# STM32MP13xx register map
File version: 1.5
CPU: CA7 r0p0, little endian, MPU, FPU, 4 interrupt priority bits
Registers are 32-bit, read-write, reset 0x0 unless marked. A register's access mark holds for its fields unless they carry their own. Offsets are from the block's base; [hi:lo] are bit positions; {n}, {i} and the like mark numbered series; 'fields as' and 'values as' point back to an identical list.

## RCC (part 3 of 7)
Base 0x50000000
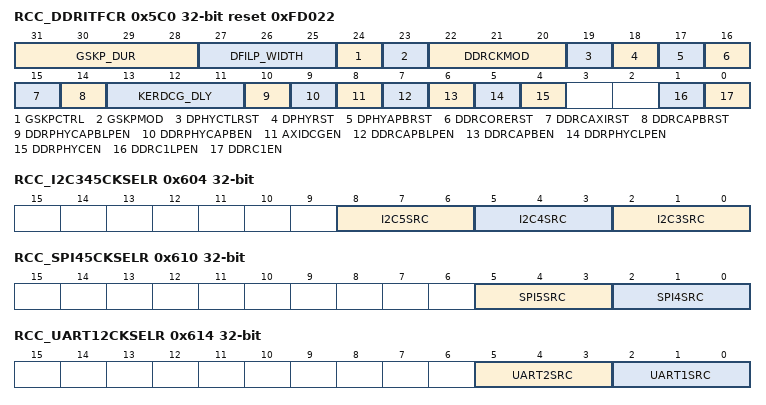
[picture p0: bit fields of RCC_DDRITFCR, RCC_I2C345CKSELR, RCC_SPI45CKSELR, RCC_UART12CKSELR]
0x5C0 RCC_DDRITFCR reset 0xFD022 — RCC DDR interface control register
  [31:28] GSKP_DUR — Glitch skipper duration in automatic mode If DDRC block is configured as secure via the corresponding DECPROT[1] field of the ETZPC register, a write access to this register field must be secure. A read access may be secure or non-secure. Written by software. This field allow the application to define the amount of time where the glitch skipper is providing the clock dphy_ker_ck instead of the clock ddrc_ker_ck to the DDRC block. This feature is only working when the glitch skipper is set in automatic mode (GSKPMOD = '1'). This delay is equal to (GSKP_DUR + 1) x 32 x Tdphy_ker_ck ...
    0=Sets a delay of 32 x Tdphy_ker_ck; 1=Sets a delay of 2 x 32 x Tdphy_ker_ck; 2=Sets a delay of 3 x 32 x Tdphy_ker_ck; 15=Sets a delay of 16 x 32 x Tdphy_ker_ck
  [27:25] DFILP_WIDTH — Minimum duration of low-power request command If DDRC block is configured as secure via the corresponding DECPROT[1] field of the ETZPC register, a write access to this register field must be secure. A read access may be secure or non-secure. Written by software. The low power request duration must always be bigger or equal to 1 microsecond. If this duration is not respected, the DDR interface behavior is not guaranteed. The application has to program properly DFILP_WIDTH in order to ensure a delay bigger or equal to 1 microsecond. Note that the delay is also dependent of the frequency of the dphy_ker_ck clock. Others: Forces a delay of 544 x Tdphy_ker_ck to be used when Fdphy_ker_ck is between 410 and 533MHz
    0=Bypass, delay disabled; 1=Forces a delay of 160 x Tdphy_ker_ck to be used when Fdphy_ker_ck is between 120 and 160 MHz; 2=Forces a delay of 224 x Tdphy_ker_ck to be used when Fdphy_ker_ck is between 160 and 220 MHz; 3=Forces a delay of 320 x Tdphy_ker_ck to be used when Fdphy_ker_ck is between 220 and 320 MHz; 4=Forces a delay of 416 x Tdphy_ker_ck to be used when Fdphy_ker_ck is between 320 and 410 MHz
  [24] GSKPCTRL — Glitch skipper (GSKP) control If DDRC block is configured as secure via the corresponding DECPROT[1] field of the ETZPC register, a write access to this register field must be secure. A read access may be secure or non-secure. Set and clear by software. This has effect only if GSKPMOD = '0'.
    0=The GSKP block is providing the clock phy_out_ck (provided by the DDRPHYC); 1=The GSKP block is providing the clock dphy_ker_ck (provided by the RCC)
  [23] GSKPMOD — Glitch Skipper (GSKP) Mode If DDRC block is configured as secure via the corresponding DECPROT[1] field of the ETZPC register, a write access to this register field must be secure. A read access may be secure or non-secure. Set and clear by software.
    0=The GSKP block is controlled by the GSKPCTRL bit; 1=The GSKP block is controlled automatically by the DFI
  [22:20] DDRCKMOD — RCC mode for DDR clock control If DDRC block is configured as secure via the corresponding DECPROT[1] field of the ETZPC register, a write access to this register field must be secure. A read access may be secure or non-secure. Written by software. This mode can be used when the application wants to maintain a clock to the DLLs in order to avoid the re-lock sequences. In this mode it is recommended to have DDRCxEN = DDRCxLPEN = DDRPHYCEN = DDRPHYCLPEN = '1'. This mode can be used when the DLLs are in bypass. In this mode it is recommended to have DDRCxEN = DDRCxLPEN = DDRPHYCEN = DDRPHYCLPEN = '1'. This mode can be used when the application wants to maintain a clock to the DLLs. In this mode it is recommended to have DDRCxEN = DDRCxLPEN = DDRPHYCEN = DDRPHYCLPEN = '1'. This mode can be used when the DLLs are in bypass. In this mode it is recommended to have DDRCxEN = DDRCxLPEN = DDRPHYCEN = DDRPHYCLPEN = '1'. other: reserved
    0=Normal mode: the gating of the dphy_ker_ck clock depends on the DDRPHYCEN, DDRPHYCLPEN and MPU mode. The gating of the ddrc_ker_ckg clock depends on the DDRCxEN, DDRCxLPEN and MPU mode. This mode must be selected during DDRC and DDRPHYC initialization phase, and if the application is using the software self-refresh (SSR).; 1=Automatic Self-Refresh mode (ASR1): the clock ddrc_ker_ckg is gated automatically according to cactive_ddrc signal. The gating of the dphy_ker_ck clock depends on the DDRPHYCEN, DDRPHYCLPEN and MPU mode.; 5=Full Automatic Self-Refresh mode (ASR2): the clocks ddrc_ker_ckg and dphy_ker_ck are gated automatically according to cactive_ddrc signal; 2=Hardware Self-Refresh mode (HSR1): the gating of the ddrc_ker_ckg clock is controlled by the AXI-Low-Power interface connected to the DDRC. The gating of the dphy_ker_ck clock depends on the DDRPHYCEN, DDRPHYCLPEN and MPU mode.; 6=Full Hardware Self-Refresh mode (HSR2): the gating of ddrc_ker_ckg and dphy_ker_ck clocks are controlled by the AXI-Low-Power interface connected to the DDRC
  [19] DPHYCTLRST — DDRPHYC Control reset If DDRPHYC block is configured as secure via the corresponding DECPROT[1] field of the ETZPC register, a write access to this register field must be secure. A read access may be secure or non-secure. Set and clear by software.
    0=does not reset the DDRPHYC Control; 1=reset the DDRPHYC Control
  [18] DPHYRST — DDRPHYC reset If DDRPHYC block is configured as secure via the corresponding DECPROT[1] field of the ETZPC register, a write access to this register field must be secure. A read access may be secure or non-secure. Set and clear by software.
    0=does not reset the DDRPHYC; 1=reset the DDRPHYC
  [17] DPHYAPBRST — DDRPHYC APB interface reset If DDRPHYC block is configured as secure via the corresponding DECPROT[1] field of the ETZPC register, a write access to this register field must be secure. A read access may be secure or non-secure. Set and clear by software.
    0=does not reset the DDRPHYC APB interface; 1=reset the DDRPHYC APB interface
  [16] DDRCORERST — DDRC core reset If DDRC block is configured as secure via the corresponding DECPROT[1] field of the ETZPC register, a write access to this register field must be secure. A read access may be secure or non-secure. Set and clear by software.
    0=does not reset the DDRC core; 1=reset the DDRC core
  [15] DDRCAXIRST — DDRC AXI interface reset If DDRC block is configured as secure via the corresponding DECPROT[1] field of the ETZPC register, a write access to this register field must be secure. A read access may be secure or non-secure. Set and clear by software.
    0=does not reset the DDRC AXI interface; 1=reset the DDRC AXI interface
  [14] DDRCAPBRST — DDRC APB interface reset If DDRC block is configured as secure via the corresponding DECPROT[1] field of the ETZPC register, a write access to this register field must be secure. A read access may be secure or non-secure. Set and clear by software.
    0=does not reset the DDRC APB interface; 1=reset the DDRC APB interface
  [13:11] KERDCG_DLY — AXIDCG delay If DDRC block is configured as secure via the corresponding DECPROT[1] field of the ETZPC register, a write access to this register field must be secure. A read access may be secure or non-secure. Set and clear by software. It represents the delay between the falling edge of the cactive_ddrc signal and the moment where the KERDCG will gate the ddrc_ker_ckg. ...
    0=1 period of ddrc_ker_ck between cactive_ddrc falling edge and the gating of ddrc_ker_ckg; 1=3 periods of ddrc_ker_ck between cactive_ddrc falling edge and the gating of ddrc_ker_ckg; 7=15 periods of ddrc_ker_ck between cactive_ddrc falling edge and the gating of ddrc_ker_ckg
  [10] DDRPHYCAPBLPEN — DDRPHYC APB clock enable during CSleep mode If DDRC block is configured as secure via the corresponding DECPROT[1] field of the ETZPC register, a write access to this register field must be secure. A read access may be secure or non-secure. Set and clear by software. This bit is controlling the gating of pclk4_dphy clock during CSleep mode.
    0=means that the APB clock is disabled in CSleep; 1=means that the APB clock is enabled in CSleep
  [9] DDRPHYCAPBEN — DDRPHYC APB clock enable If DDRC block is configured as secure via the corresponding DECPROT[1] field of the ETZPC register, a write access to this register field must be secure. A read access may be secure or non-secure. Set and clear by software. This bit is controlling the gating of pclk4_dphy clock.
    0=means that the APB clock is disabled; 1=means that the APB clock is enabled
  [8] AXIDCGEN — AXIDCG enable during MPU CRun mode If DDRC block is configured as secure via the corresponding DECPROT[1] field of the ETZPC register, a write access to this register field must be secure. A read access may be secure or non-secure. Set and clear by software. When the dynamic clock gating is disabled, the clock is always provided to the DDRC if provided by the RCC.
    0=means that the dynamic clock gating of AXIDCG[2:1] is disabled during MPU CRun,; 1=means that the dynamic clock gating of AXIDCG[2:1] is enabled during MPU CRun
  [7] DDRCAPBLPEN — DDRC APB clock enable during CSleep mode If DDRC block is configured as secure via the corresponding DECPROT[1] field of the ETZPC register, a write access to this register field must be secure. A read access may be secure or non-secure. Set and clear by software. This bit is controlling the gating of pclk4_ddrc clock during CSleep mode.
    values as DDRPHYCAPBLPEN
  [6] DDRCAPBEN — DDRC APB clock enable If DDRC block is configured as secure via the corresponding DECPROT[1] field of the ETZPC register, a write access to this register field must be secure. A read access may be secure or non-secure. Set and clear by software. This bit is controlling the gating of pclk4_ddrc clock.
    values as DDRPHYCAPBEN
  [5] DDRPHYCLPEN — DDRPHYC peripheral clocks enable during CSleep mode If DDRPHYC block is configured as secure via the corresponding DECPROT[1] field of the ETZPC register, a write access to this register field must be secure. A read access may be secure or non-secure. Set and clear by software. This bit is controlling the gating of dphy_ker_ck and pclk4_dphy in CSleep
    0=means that the peripheral clocks are disabled in CSleep; 1=means that the peripheral clocks are enabled in CSleep
  [4] DDRPHYCEN — DDRPHYC peripheral clocks enable If DDRPHYC block is configured as secure via the corresponding DECPROT[1] field of the ETZPC register, a write access to this register field must be secure. A read access may be secure or non-secure. Set and clear by software. This bit is controlling the gating of dphy_ker_ck and pclk4_dphy
    0=means that the peripheral clocks are disabled; 1=means that the peripheral clocks are enabled
  [1] DDRC1LPEN — DDRC port 1 peripheral clocks enable during CSleep mode If DDRC block is configured as secure via the corresponding DECPROT[1] field of the ETZPC register, a write access to this register field must be secure. A read access may be secure or non-secure. Set and clear by software. This bit is controlling the gating of ddrc_ker_ckg, aclk1_ddrc and pclk4_ddrc in CSleep.
    values as DDRPHYCLPEN
  [0] DDRC1EN — DDRC port 1 peripheral clocks enable If DDRC block is configured as secure via the corresponding DECPROT[1] field of the ETZPC register, a write access to this register field must be secure. A read access may be secure or non-secure. Set and clear by software. This bit is controlling the gating of ddrc_ker_ckg, aclk1_ddrc and pclk4_ddrc clocks.
    0=Means that the DDRC peripheral clocks are disabled; 1=Means that the DDRC peripheral clocks are enabled
0x600 RCC_I2C12CKSELR — RCC I2C1 and I2C2 kernel clock selection register
  [2:0] I2C12SRC — I2C1 and I2C2 kernel clock source selection Written by software. others: reserved, the kernel clock is disabled
    0=pclk1 clock selected as kernel peripheral clock (default after reset); 1=pll4_r_ck clock selected as kernel peripheral clock; 2=hsi_ker_ck clock selected as kernel peripheral clock; 3=csi_ker_ck clock selected as kernel peripheral clock
0x604 RCC_I2C345CKSELR — RCC I2C3, I2C4 and I2C5 kernel clock selection register.
  [all] fields
    0=pclk6 clock selected as kernel peripheral clock (default after reset); 1=pll4_r_ck clock selected as kernel peripheral clock; 2=hsi_ker_ck clock selected as kernel peripheral clock; 3=csi_ker_ck clock selected as kernel peripheral clock
  [8:6] I2C5SRC — I2C5 kernel clock source selection If I2C5 block is configured as secure via the corresponding DECPROT[1] field of the ETZPC register, a write access to this register field must be secure. A read access may be secure or non-secure. Written by software. others: reserved, the kernel clock is disabled
  [5:3] I2C4SRC — I2C4 kernel clock source selection If I2C4 block is configured as secure via the corresponding DECPROT[1] field of the ETZPC register, a write access to this register field must be secure. A read access may be secure or non-secure. Written by software. others: reserved, the kernel clock is disabled
  [2:0] I2C3SRC — I2C3 kernel clock source selection If I2C3 block is configured as secure via the corresponding DECPROT[1] field of the ETZPC register, a write access to this register field must be secure. A read access may be secure or non-secure. Written by software. others: reserved, the kernel clock is disabled
0x608 RCC_SPI2S1CKSELR — RCC SPI/I2S1 kernel clock selection register
  [2:0] SPI1SRC — SPI/I2S1 kernel clock source selection Written by software. others: reserved, the kernel clock is disabled
    0=pll4_p_ck clock selected as kernel peripheral clock (default after reset); 1=pll3_q_ck clock selected as kernel peripheral clock; 2=I2S_CKIN clock selected as kernel peripheral clock; 3=per_ck clock selected as kernel peripheral clock; 4=pll3_r_ck clock selected as kernel peripheral clock
0x60C RCC_SPI2S23CKSELR — RCC SPI/I2S2 and SPI/I2S3 kernel clock selection register
  [2:0] SPI23SRC — SPI/I2S2 and SPI/I2S3 kernel clock source selection Written by software. others: reserved, the kernel clock is disabled
    values as RCC_SPI2S1CKSELR.SPI1SRC
0x610 RCC_SPI45CKSELR — RCC SPI/I2S4 and SPI5 kernel clock selection register
  [5:3] SPI5SRC — SPI5 kernel clock source selection If SPI5 block is configured as secure via the corresponding DECPROT[1] field of the ETZPC register, a write access to this register field must be secure. A read access may be secure or non-secure. Written by software. others: reserved, the kernel clock is disabled
    0=pclk6 clock selected as kernel peripheral clock (default after reset); 1=pll4_q_ck clock selected as kernel peripheral clock; 2=hsi_ker_ck clock selected as kernel peripheral clock; 3=csi_ker_ck clock selected as kernel peripheral clock; 4=hse_ker_ck clock selected as kernel peripheral clock
  [2:0] SPI4SRC — SPI/I2S4 kernel clock source selection If SPI/I2S4 block is configured as secure via the corresponding DECPROT[1] field of the ETZPC register, a write access to this register field must be secure. A read access may be secure or non-secure. Written by software. others: reserved, the kernel clock is disabled
    0=pclk6 clock selected as kernel peripheral clock (default after reset); 1=pll4_q_ck clock selected as kernel peripheral clock; 2=hsi_ker_ck clock selected as kernel peripheral clock; 3=csi_ker_ck clock selected as kernel peripheral clock; 4=hse_ker_ck clock selected as kernel peripheral clock; 5=I2S_CKIN clock selected as kernel peripheral clock
0x614 RCC_UART12CKSELR — RCC USART1 and USART2 kernel clock selection register
  [5:3] UART2SRC — USART2 kernel clock source selection If USART2 block is configured as secure via the corresponding DECPROT[1] field of the ETZPC register, a write access to this register field must be secure. A read access may be secure or non-secure. Written by software. others: reserved, the kernel clock is disabled
    0=pclk6 clock selected as kernel peripheral clock (default after reset); 1=pll3_q_ck clock selected as kernel peripheral clock; 2=hsi_ker_ck clock selected as kernel peripheral clock; 3=csi_ker_ck clock selected as kernel peripheral clock; 4=pll4_q_ck clock selected as kernel peripheral clock; 5=hse_ker_ck clock selected as kernel peripheral clock
  [2:0] UART1SRC — USART1 kernel clock source selection If USART1 block is configured as secure via the corresponding DECPROT[1] field of the ETZPC register, a write access to this register field must be secure. A read access may be secure or non-secure. Written by software. others: reserved, the kernel clock is disabled
    values as UART2SRC
0x618 RCC_UART35CKSELR — RCC USART3 and UART5 kernel clock selection register
  [2:0] UART35SRC — USART3 and UART5 kernel clock source selection Written by software. others: reserved, the kernel clock is disabled
    0=pclk1 clock selected as kernel peripheral clock (default after reset); 1=pll4_q_ck clock selected as kernel peripheral clock; 2=hsi_ker_ck clock selected as kernel peripheral clock; 3=csi_ker_ck clock selected as kernel peripheral clock; 4=hse_ker_ck clock selected as kernel peripheral clock
0x61C RCC_UART4CKSELR — RCC UART4 kernel clock selection register
  [2:0] UART4SRC — UART4 kernel clock source selection Written by software. others: reserved, the kernel clock is disabled
    values as RCC_UART35CKSELR.UART35SRC
0x620 RCC_UART6CKSELR — RCC USART6 kernel clock selection register
  [2:0] UART6SRC — USART6 kernel clock source selection Written by software. others: reserved, the kernel clock is disabled
    0=pclk2 clock selected as kernel peripheral clock (default after reset); 1=pll4_q_ck clock selected as kernel peripheral clock; 2=hsi_ker_ck clock selected as kernel peripheral clock; 3=csi_ker_ck clock selected as kernel peripheral clock; 4=hse_ker_ck clock selected as kernel peripheral clock
0x624 RCC_UART78CKSELR — RCC UART7 and UART8 kernel clock selection register
  [2:0] UART78SRC — UART7 and UART8 kernel clock source selection Written by software. others: reserved, the kernel clock is disabled
    values as RCC_UART35CKSELR.UART35SRC
0x628 RCC_LPTIM1CKSELR — RCC LPTIM1 kernel clock selection register
  [2:0] LPTIM1SRC — LPTIM1 kernel clock source selection Written by software. others: the kernel clock is disabled
    0=pclk1 clock selected as kernel peripheral clock (default after reset); 1=pll4_p_ck clock selected as kernel peripheral clock; 2=pll3_q_ck clock selected as kernel peripheral clock; 3=lse_ck clock selected as kernel peripheral clock; 4=lsi_ck clock selected as kernel peripheral clock; 5=per_ck clock selected as kernel peripheral clock
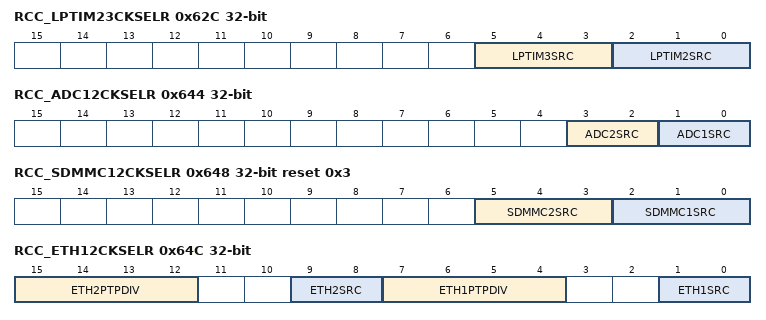
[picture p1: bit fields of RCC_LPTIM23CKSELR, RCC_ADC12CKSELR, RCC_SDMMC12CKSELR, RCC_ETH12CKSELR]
0x62C RCC_LPTIM23CKSELR — RCC LPTIM2 and LPTIM3 kernel clock selection register
  [5:3] LPTIM3SRC — LPTIM3 kernel clock source selection If LPTIM3 block is configured as secure via the corresponding DECPROT[1] field of the ETZPC register, a write access to this register field must be secure. A read access may be secure or non-secure. Written by software. others: the kernel clock is disabled
    0=pclk3 clock selected as kernel peripheral clock (default after reset); 1=pll4_q_ck clock selected as kernel peripheral clock; 2=per_ck clock selected as kernel peripheral clock; 3=lse_ck clock selected as kernel peripheral clock; 4=lsi_ck clock selected as kernel peripheral clock
  [2:0] LPTIM2SRC — LPTIM2 kernel clock source selection If LPTIM2 block is configured as secure via the corresponding DECPROT[1] field of the ETZPC register, a write access to this register field must be secure. A read access may be secure or non-secure. Written by software. others: the kernel clock is disabled
    values as LPTIM3SRC
0x630 RCC_LPTIM45CKSELR — RCC LPTIM4 and LPTIM5 kernel clock selection register
  [2:0] LPTIM45SRC — LPTIM4 and LPTIM5 kernel clock source selection Written by software. others: the kernel clock is disabled
    0=pclk3 clock selected as kernel peripheral clock (default after reset); 1=pll4_p_ck clock selected as kernel peripheral clock; 2=pll3_q_ck clock selected as kernel peripheral clock; 3=lse_ck clock selected as kernel peripheral clock; 4=lsi_ck clock selected as kernel peripheral clock; 5=per_ck clock selected as kernel peripheral clock
0x634 RCC_SAI1CKSELR — RCC SAI1 kernel clock selection register
  [2:0] SAI1SRC — SAI1 and DFSDM kernel clock source selection Written by software. others: reserved, the kernel clock is disabled
    0=pll4_q_ck clock selected as kernel peripheral clock (default after reset); 1=pll3_q_ck clock selected as kernel peripheral clock; 2=I2S_CKIN clock selected as kernel peripheral clock; 3=per_ck clock selected as kernel peripheral clock; 4=pll3_r_ck clock selected as kernel peripheral clock
0x638 RCC_SAI2CKSELR — RCC SAI2 kernel clock selection register
  [2:0] SAI2SRC — SAI2 kernel clock source selection Written by software. others: reserved, the kernel clock is disabled
    0=pll4_q_ck clock selected as kernel peripheral clock (default after reset); 1=pll3_q_ck clock selected as kernel peripheral clock; 2=I2S_CKIN clock selected as kernel peripheral clock; 3=per_ck clock selected as kernel peripheral clock; 4=spdif_ck_symb clock from SPDIFRX selected as kernel peripheral clock; 5=pll3_r_ck clock selected as kernel peripheral clock
0x63C RCC_FDCANCKSELR — RCC FDCAN kernel clock selection register
  [1:0] FDCANSRC — FDCAN kernel clock source selection Written by software.
    0=hse_ker_ck clock selected as kernel peripheral clock (default after reset); 1=pll3_q_ck clock selected as kernel peripheral clock; 2=pll4_q_ck clock selected as kernel peripheral clock; 3=pll4_r_ck clock selected as kernel peripheral clock
0x640 RCC_SPDIFCKSELR — RCC SPDIFRX kernel clock selection register
  [1:0] SPDIFSRC — SPDIFRX kernel clock source selection Written by software. others: reserved, the kernel clock is disabled
    0=pll4_p_ck clock selected as kernel peripheral clock (default after reset); 1=pll3_q_ck clock selected as kernel peripheral clock; 2=hsi_ker_ck clock selected as kernel peripheral clock
0x644 RCC_ADC12CKSELR — This register may be separately and securely write-protected at a field level depending on the secure state of the corresponding peripheral, i.e. depending on the corresponding DECPROT[1] field of the ETZPC register. This register is used to control the selection of the kernel clock for the (AHB2) ADC1 and ADC2 blocks. Note that changing the clock source on-the-fly is allowed, and will not generate any timing violation, however the user has to ensure that both the previous and the new clock sources are present during the switching, and for the whole transition time. Refer to SectionÂ : Clock enabling delays.
  [3:2] ADC2SRC — ADC2 kernel clock source selection If ADC2 block is configured as secure via the corresponding DECPROT[1] field of the ETZPC register, a write access to this register field must be secure. A read access may be secure or non-secure. Written by software. others: the kernel clock is disabled
    0=pll4_r_ck clock selected as kernel peripheral clock (default after reset); 1=per_ck clock selected as kernel peripheral clock; 2=pll3_q_ck clock selected as kernel peripheral clock
  [1:0] ADC1SRC — ADC1 kernel clock source selection If ADC1 block is configured as secure via the corresponding DECPROT[1] field of the ETZPC register, a write access to this register field must be secure. A read access may be secure or non-secure. Written by software. others: the kernel clock is disabled
    values as ADC2SRC
0x648 RCC_SDMMC12CKSELR reset 0x3 — This register may be separately and securely write-protected at a field level depending on the secure state of the corresponding peripheral, i.e. depending on the corresponding DECPROT[1] field of the ETZPC register. This register is used to control the selection of the kernel clock for the (AHB6) SDMMC1 and SDMMC2. Note that changing the clock source on-the-fly is allowed, and will not generate any timing violation, however the user has to ensure that both the previous and the new clock sources are present during the switching, and for the whole transition time. Refer to SectionÂ : Clock enabling delays.
  [5:3] SDMMC2SRC — SDMMC2 kernel clock source selection If SDMMC2 block is configured as secure via the corresponding DECPROT[1] field of the ETZPC register, a write access to this register field must be secure. A read access may be secure or non-secure. Written by software. others: reserved, the kernel clock is disabled
    0=hclk6 clock selected as kernel peripheral clock; 1=pll3_r_ck clock selected as kernel peripheral clock; 2=pll4_p_ck clock selected as kernel peripheral clock; 3=hsi_ker_ck clock selected as kernel peripheral clock (default after reset)
  [2:0] SDMMC1SRC — SDMMC1 kernel clock source selection If SDMMC1 block is configured as secure via the corresponding DECPROT[1] field of the ETZPC register, a write access to this register field must be secure. A read access may be secure or non-secure. Written by software. others: reserved, the kernel clock is disabled
    values as SDMMC2SRC
0x64C RCC_ETH12CKSELR — This register may be separately and securely write-protected at a field level depending on the secure state of the corresponding peripheral, i.e. depending on the corresponding DECPROT[1] field of the ETZPC register. This register is used to control the selection of the kernel clock for the ETH1 and ETH2 blocks. Note that changing the clock source on-the-fly is allowed, and will not generate any timing violation, however the user has to ensure that both the previous and the new clock sources are present during the switching, and for the whole transition time. Refer to SectionÂ : Clock enabling delays.
  [15:12] ETH2PTPDIV — ETH2 clock divider for Precision Time Protocol (PTP) If ETH2 block is configured as secure via the corresponding DECPROT[1] field of the ETZPC register, a write access to this register field must be secure. A read access may be secure or non-secure. Written by software to configure the divider value. ...
    0=bypass (default after reset); 1=division by 2; 2=division by 3; 15=division by 16
  [9:8] ETH2SRC — ETH2 kernel clock source selection If ETH2 block is configured as secure via the corresponding DECPROT[1] field of the ETZPC register, a write access to this register field must be secure. A read access may be secure or non-secure. Written by software. others: the kernel clock is disabled
    0=pll4_p_ck clock selected as kernel peripheral clock (default after reset); 1=pll3_q_ck clock selected as kernel peripheral clock
  [7:4] ETH1PTPDIV — ETH1 clock divider for Precision Time Protocol (PTP) If ETH1 block is configured as secure via the corresponding DECPROT[1] field of the ETZPC register, a write access to this register field must be secure. A read access may be secure or non-secure. Written by software to configure the divider value. ...
    values as ETH2PTPDIV
  [1:0] ETH1SRC — ETH1 kernel clock source selection If ETH1 block is configured as secure via the corresponding DECPROT[1] field of the ETZPC register, a write access to this register field must be secure. A read access may be secure or non-secure. Written by software. others: the kernel clock is disabled
    values as ETH2SRC
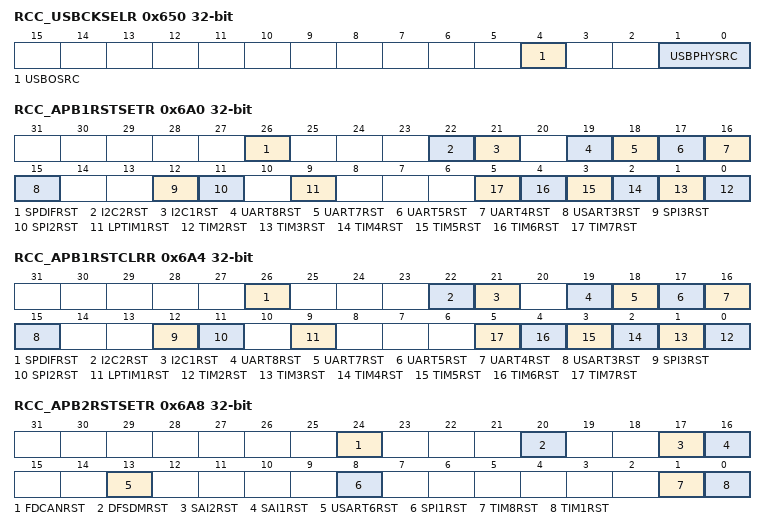
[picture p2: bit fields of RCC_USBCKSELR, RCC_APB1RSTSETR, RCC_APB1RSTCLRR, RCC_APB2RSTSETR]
0x650 RCC_USBCKSELR — This register may be separately and securely write-protected at a field level depending on the secure state of the corresponding peripheral, i.e. depending on the corresponding DECPROT[1] field of the ETZPC register. This register is used to control the selection of the kernel clock for the USBPHY PLL of the USB Host (USBH) and the USB On-The-Go (USBO). It also controls the pre-divider for the reference clock for the USBPHY. Note that changing the clock source on-the-fly is allowed, and will not generate any timing violation, however the user has to ensure that both the previous and the new clock sources are present during the switching, and for the whole transition time. Refer to SectionÂ : Clock enabling delays.
  [4] USBOSRC — USB OTG kernel clock source selection If USBO block is configured as secure via the corresponding DECPROT[1] field of the ETZPC register, a write access to this register field must be secure. A read access may be secure or non-secure. Written by software.
    0=pll4_r_ck clock selected as kernel peripheral clock (default after reset); 1=clock provided by the USB PHY (rcc_ck_usbo_48m) selected as kernel peripheral clock
  [1:0] USBPHYSRC — USB PHY kernel clock source selection If USBPHY block is configured as secure via the corresponding DECPROT[1] field of the ETZPC register, a write access to this register field must be secure. A read access may be secure or non-secure. Written by software. other: clock disabled
    0=hse_ker_ck clock selected as kernel peripheral clock (default after reset); 1=pll4_r_ck clock selected as kernel peripheral clock; 2=hse_ker_ck/2 clock selected as kernel peripheral clock
0x654 RCC_QSPICKSELR — If (AHB6) QUADSPI is configured as secure via the corresponding DECPROT[1] field of the ETZPC register, a write access to this register must be secure. A read access may be secure or non-secure. This register is used to control the selection of the kernel clock for the QUADSPI. Note that changing the clock source on-the-fly is allowed, and will not generate any timing violation, however the user has to ensure that both the previous and the new clock sources are present during the switching, and for the whole transition time. Refer to SectionÂ : Clock enabling delays.
  [1:0] QSPISRC — QUADSPI kernel clock source selection Written by software.
    0=aclk clock selected as kernel peripheral clock (default after reset); 1=pll3_r_ck clock selected as kernel peripheral clock; 2=pll4_p_ck clock selected as kernel peripheral clock; 3=per_ck clock selected as kernel peripheral clock
0x658 RCC_FMCCKSELR — If (AHB6) FMC is configured as secure via the corresponding DECPROT[1] field of the ETZPC register, a write access to this register must be secure. A read access may be secure or non-secure. This register is used to control the selection of the kernel clock for the FMC block. Note that changing the clock source on-the-fly is allowed, and will not generate any timing violation, however the user has to ensure that both the previous and the new clock sources are present during the switching, and for the whole transition time. Refer to SectionÂ : Clock enabling delays.
  [1:0] FMCSRC — FMC kernel clock source selection Written by software.
    values as RCC_QSPICKSELR.QSPISRC
0x65C RCC_RNG1CKSELR — If (AHB5) RNG1 is configured as secure via the corresponding DECPROT[1] field of the ETZPC register, a write access to this register must be secure. A read access may be secure or non-secure. This register is used to control the selection of the kernel clock for the RNG1. Note that changing the clock source on-the-fly is allowed, and will not generate any timing violation, however the user has to ensure that both the previous and the new clock sources are present during the switching, and for the whole transition time. Refer to SectionÂ : Clock enabling delays.
  [1:0] RNG1SRC — RNG1 kernel clock source selection Written by software.
    0=csi_ker_ck clock selected as kernel peripheral clock (default after reset); 1=pll4_r_ck clock selected as kernel peripheral clock; 2=lse_ck clock selected as kernel peripheral clock; 3=lsi_ck clock selected as kernel peripheral clock
0x660 RCC_STGENCKSELR — If (APB5) STGENC is configured as secure via the corresponding DECPROT[1] field of the ETZPC register, a write access to this register must be secure. A read access may be secure or non-secure. STGEN is a dual APB interface IP, with STGENC APB5 controller part which may be secure or non-secure depending on the corresponding DECPROT[1]. Its other STGENRO APB4 read-only interface is non-secure. This register is used to select the peripheral clock for the STGEN block. Note that this clock is used to provide a time reference for the application. Refer to SectionÂ : Clock enabling delays.
  [1:0] STGENSRC — Oscillator selection for kernel clock Set and cleared by software. others: Clock disabled
    0=hsi_ker_ck clock selected (default after reset); 1=hse_ker_ck clock selected
0x664 RCC_DCMIPPCKSELR — If (APB4) DCMIPP is configured as secure via the corresponding DECPROT[1] field of the ETZPC register, a write access to this register must be secure. A read access may be secure or non-secure. This register is used to control the selection of the kernel clock for the DCMIPP block. Note that changing the clock source on-the-fly is allowed, and will not generate any timing violation, however the user has to ensure that both the previous and the new clock sources are present during the switching, and for the whole transition time. Refer to SectionÂ : Clock enabling delays.
  [1:0] DCMIPPSRC — DCMIPP kernel clock source selection Written by software.
    0=aclk clock selected as kernel peripheral clock (default after reset); 1=pll2_q_ck clock selected as kernel peripheral clock; 2=pll4_p_ck clock selected as kernel peripheral clock; 3=per_ck clock selected as kernel peripheral clock
0x668 RCC_SAESCKSELR — If (AHB5) SAES is configured as secure via the corresponding DECPROT[1] field of the ETZPC register, a write access to this register must be secure. A read access may be secure or non-secure. This register is used to control the selection of the kernel clock for the SAES block. Note that changing the clock source on-the-fly is allowed, and will not generate any timing violation, however the user has to ensure that both the previous and the new clock sources are present during the switching, and for the whole transition time. Refer to SectionÂ : Clock enabling delays.
  [1:0] SAESSRC — SAES kernel clock source selection Written by software.
    0=axiss_ck clock selected as kernel peripheral clock (default after reset); 1=per_ck clock selected as kernel peripheral clock; 2=pll_4_r_ck clock selected as kernel peripheral clock; 3=lsi_ck clock selected as kernel peripheral clock
0x6A0 RCC_APB1RSTSETR — This register is used to activate the reset of the corresponding peripheral. Writing '0' has no effect, reading will return the effective values of the corresponding bits. Writing a '1' activates the reset of the corresponding peripheral.
  [all] fields
    0=Writing '0' has no effect, reading '0' means that the block reset is released; 1=Writing '1' asserts the block reset, reading '1' means that the block reset is asserted
  [26] SPDIFRST — SPDIFRX block reset Set by software.
  [22] I2C2RST — I2C2 block reset Set by software.
  [21] I2C1RST — I2C1 block reset Set by software.
  [19] UART8RST — UART8 block reset Set by software.
  [18] UART7RST — UART7 block reset Set by software.
  [17] UART5RST — UART5 block reset Set by software.
  [16] UART4RST — UART4 block reset Set by software.
  [15] USART3RST — USART3 block reset Set by software.
  [12] SPI3RST — SPI3 block reset Set by software.
  [11] SPI2RST — SPI/I2S2 block reset Set by software.
  [9] LPTIM1RST — LPTIM1 block reset Set by software.
  [n-2] TIM{n}RST (n=2..7) — TIM{n} block reset Set by software.
0x6A4 RCC_APB1RSTCLRR — This register is used to release the reset of the corresponding peripheral. Writing '0' has no effect, reading will return the effective values of the corresponding bits. Writing a '1' releases the reset of the corresponding peripheral.
  [all] fields
    0=Writing '0' has no effect, reading '0' means that the block reset is released; 1=Writing '1' release the block reset, reading '1' means that the block reset is asserted
  [26] SPDIFRST — SPDIFRX block reset Cleared by software.
  [22] I2C2RST — I2C2 block reset Cleared by software.
  [21] I2C1RST — I2C1 block reset Cleared by software.
  [19] UART8RST — UART8 block reset Cleared by software.
  [18] UART7RST — UART7 block reset Cleared by software.
  [17] UART5RST — UART5 block reset Cleared by software.
  [16] UART4RST — UART4 block reset Cleared by software.
  [15] USART3RST — USART3 block reset Cleared by software.
  [12] SPI3RST — SPI3 block reset Cleared by software.
  [11] SPI2RST — SPI2 block reset Cleared by software.
  [9] LPTIM1RST — LPTIM1 block reset Cleared by software.
  [n-2] TIM{n}RST (n=2..7) — TIM{n} block reset Cleared by software.
0x6A8 RCC_APB2RSTSETR — This register is used to activate the reset of the corresponding peripheral. Writing '0' has no effect, reading will return the effective values of the corresponding bits. Writing a '1' activates the reset of the corresponding peripheral.
  [all] fields
    values as the fields of RCC_APB1RSTSETR
  [24] FDCANRST — FDCAN block reset Set by software.
  [20] DFSDMRST — DFSDM block reset Set by software.
  [17] SAI2RST — SAI2 block reset Set by software.
  [16] SAI1RST — SAI1 block reset Set by software.
  [13] USART6RST — USART6 block reset Set by software.
  [8] SPI1RST — SPI/I2S1 block reset Set by software.
  [1] TIM8RST — TIM8 block reset Set by software.
  [0] TIM1RST — TIM1 block reset Set by software.
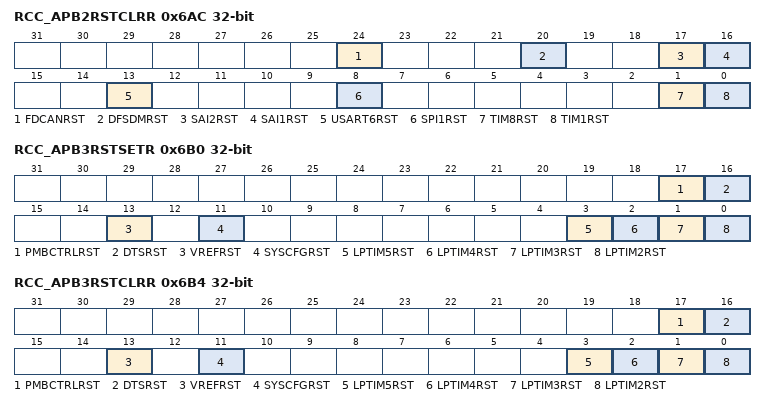
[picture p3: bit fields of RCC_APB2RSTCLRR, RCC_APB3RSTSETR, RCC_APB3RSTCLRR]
0x6AC RCC_APB2RSTCLRR — This register is used to release the reset of the corresponding peripheral. Writing '0' has no effect, reading will return the effective values of the corresponding bits. Writing a '1' releases the reset of the corresponding peripheral.
  [all] fields
    0=Writing '0' has no effect, reading '0' means that the block reset is released; 1=Writing '1' releases the block reset, reading '1' means that the block reset is asserted
  [24] FDCANRST — FDCAN block reset Cleared by software.
  [20] DFSDMRST — DFSDM block reset Cleared by software.
  [17] SAI2RST — SAI2 block reset Cleared by software.
  [16] SAI1RST — SAI1 block reset Cleared by software.
  [13] USART6RST — USART6 block reset Cleared by software.
  [8] SPI1RST — SPI/I2S1 block reset Cleared by software.
  [1] TIM8RST — TIM8 block reset Cleared by software.
  [0] TIM1RST — TIM1 block reset Cleared by software.
0x6B0 RCC_APB3RSTSETR — This register may be separately and securely write-protected at a field level, as detailed in the following register fields description. This register is used to activate the reset of the corresponding peripheral. Writing '0' has no effect, reading will return the effective values of the corresponding bits. Writing a '1' activates the reset of the corresponding peripheral.
  [17] PMBCTRLRST — PMBCTRL block reset (non-user): this bit is present in the RTL and is internally used as: SPIRIT parameter RTLPRESENT
  [16] DTSRST — DTS block reset Set by software.
    values as the fields of RCC_APB1RSTSETR
  [13] VREFRST — VREF block reset If VREF block is configured as secure via the corresponding DECPROT[1] field of the ETZPC register, a write access to this register field must be secure. A read access may be secure or non-secure. Set by software.
    values as the fields of RCC_APB1RSTSETR
  [11] SYSCFGRST — SYSCFG block reset A write access to this register field must be secure. A read access may be secure or non-secure. Set by (secure) software.
    values as the fields of RCC_APB1RSTSETR
  [3] LPTIM5RST — LPTIM5 block reset Set by software.
    values as the fields of RCC_APB1RSTSETR
  [2] LPTIM4RST — LPTIM4 block reset Set by software.
    values as the fields of RCC_APB1RSTSETR
  [1] LPTIM3RST — LPTIM3 block reset Set by software. If LPTIM3 block is configured as secure via the corresponding DECPROT[1] field of the ETZPC register, a write access to this register field must be secure. A read access may be secure or non-secure.
    values as the fields of RCC_APB1RSTSETR
  [0] LPTIM2RST — LPTIM2 block reset Set by software. If LPTIM3 block is configured as secure via the corresponding DECPROT[1] field of the ETZPC register, a write access to this register field must be secure. A read access may be secure or non-secure.
    values as the fields of RCC_APB1RSTSETR
0x6B4 RCC_APB3RSTCLRR — This register may be separately and securely write-protected at a field level, as detailed in the following register fields description. This register is used to release the reset of the corresponding peripheral. Writing '0' has no effect, reading will return the effective values of the corresponding bits. Writing a '1' releases the reset of the corresponding peripheral.
  [17] PMBCTRLRST — PMBCTRL block reset (non-user): this bit is present in the RTL and is internally used as: SPIRIT parameter RTLPRESENT
  [16] DTSRST — DTS block reset Cleared by software.
    values as the fields of RCC_APB2RSTCLRR
  [13] VREFRST — VREF block reset If VREF block is configured as secure via the corresponding DECPROT[1] field of the ETZPC register, a write access to this register field must be secure. A read access may be secure or non-secure. Cleared by software.
    values as the fields of RCC_APB2RSTCLRR
  [11] SYSCFGRST — SYSCFG block reset A write access to this register field must be secure. A read access may be secure or non-secure. Cleared by (secure) software.
    values as the fields of RCC_APB2RSTCLRR
  [3] LPTIM5RST — LPTIM5 block reset Cleared by software.
    values as the fields of RCC_APB2RSTCLRR
  [2] LPTIM4RST — LPTIM4 block reset Cleared by software.
    values as the fields of RCC_APB2RSTCLRR
  [1] LPTIM3RST — LPTIM3 block reset If LPTIM3 block is configured as secure via the corresponding DECPROT[1] field of the ETZPC register, a write access to this register field must be secure. A read access may be secure or non-secure. Cleared by software.
    values as the fields of RCC_APB2RSTCLRR
  [0] LPTIM2RST — LPTIM2 block reset If LPTIM2 block is configured as secure via the corresponding DECPROT[1] field of the ETZPC register, a write access to this register field must be secure. A read access may be secure or non-secure. Cleared by software.
    values as the fields of RCC_APB2RSTCLRR
